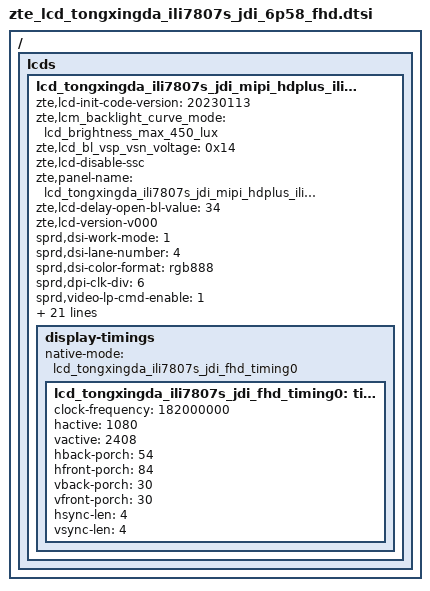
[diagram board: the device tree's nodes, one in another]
/ {
	fragment {
		target-path = "/";
		__overlay__ {
			lcds {
				lcd_tongxingda_ili7807s_jdi_mipi_hdplus_ilitek: lcd_tongxingda_ili7807s_jdi_mipi_hdplus_ilitek{
					zte,lcd-init-code-version = "20230113";

					zte,lcm_backlight_curve_mode = "lcd_brightness_max_450_lux";
					zte,lcd_bl_vsp_vsn_voltage = <0x14>;
					zte,lcd-disable-ssc;
					zte,panel-name = "lcd_tongxingda_ili7807s_jdi_mipi_hdplus_ilitek";
					zte,lcd-delay-open-bl-value = <34>;
					zte,lcd-version-v000;

					sprd,dsi-work-mode = <1>;
					sprd,dsi-lane-number = <4>;
					sprd,dsi-color-format = "rgb888";

					sprd,dpi-clk-div = <6>;
					sprd,video-lp-cmd-enable = <1>;
					sprd,hporch-lp-disable = <1>;

					sprd,phy-bit-clock = <1092000>;
					sprd,phy-escape-clock = <20000>;/* kHz */

					sprd,width-mm = <68430>;
					sprd,height-mm = <152570>;

					sprd,esd-check-enable = <1>;/* 0:close , 1:open */
					sprd,esd-check-mode = <1>;/* 0:REG ,1:TE  */
					sprd,esd-check-period = <2000>;
					sprd,esd-check-register = <0x0A>;
					sprd,esd-check-value = <0x9C>;

					sprd,dphy-taget-val = <5>;

					sprd,reset-on-sequence = <1 5>, <0 10>, <1 80>, <0 10>, <1 35>;
					sprd,reset-off-sequence = <1 20>;

					sprd,use-dcs-write;
		sprd,initial-command = [
				29 00 00 04 FF 78 07 01
				29 00 00 02 00 41
				29 00 00 02 01 42
				29 00 00 02 02 42
				29 00 00 02 03 2F
				29 00 00 02 04 c3
				29 00 00 02 05 03
				29 00 00 02 06 00
				29 00 00 02 07 0a

				29 00 00 02 08 01
				29 00 00 02 09 01
				29 00 00 02 0a 73
				29 00 00 02 0b 00
				29 00 00 02 0c 00
				29 00 00 02 0e 00

				29 00 00 02 16 01
				29 00 00 02 17 00
				29 00 00 02 18 30
				29 00 00 02 19 00
				29 00 00 02 1a 20
				29 00 00 02 1c 09

				29 00 00 02 31 07
				29 00 00 02 32 07
				29 00 00 02 33 07
				29 00 00 02 34 08
				29 00 00 02 35 07
				29 00 00 02 36 10
				29 00 00 02 37 07
				29 00 00 02 38 07
				29 00 00 02 39 1b
				29 00 00 02 3a 1a
				29 00 00 02 3b 19
				29 00 00 02 3c 18
				29 00 00 02 3d 07
				29 00 00 02 3e 07
				29 00 00 02 3f 07
				29 00 00 02 40 07
				29 00 00 02 41 07
				29 00 00 02 42 30
				29 00 00 02 43 2e
				29 00 00 02 44 2f
				29 00 00 02 45 07
				29 00 00 02 46 34
				29 00 00 02 47 35
				29 00 00 02 48 36

				29 00 00 02 49 07
				29 00 00 02 4a 29
				29 00 00 02 4b 07
				29 00 00 02 4c 00
				29 00 00 02 4d 07
				29 00 00 02 4e 10
				29 00 00 02 4f 07
				29 00 00 02 50 07
				29 00 00 02 51 1b
				29 00 00 02 52 1a
				29 00 00 02 53 19
				29 00 00 02 54 18
				29 00 00 02 55 07
				29 00 00 02 56 07
				29 00 00 02 57 07
				29 00 00 02 58 07
				29 00 00 02 59 07
				29 00 00 02 5a 30
				29 00 00 02 5b 2e
				29 00 00 02 5c 2f
				29 00 00 02 5d 07
				29 00 00 02 5e 34
				29 00 00 02 5f 35
				29 00 00 02 60 36

				29 00 00 02 61 07
				29 00 00 02 62 07
				29 00 00 02 63 07
				29 00 00 02 64 08
				29 00 00 02 65 07
				29 00 00 02 66 14
				29 00 00 02 67 07
				29 00 00 02 68 07
				29 00 00 02 69 18
				29 00 00 02 6a 19
				29 00 00 02 6b 1a
				29 00 00 02 6c 1b
				29 00 00 02 6d 07
				29 00 00 02 6e 07
				29 00 00 02 6f 07
				29 00 00 02 70 07
				29 00 00 02 71 07
				29 00 00 02 72 30
				29 00 00 02 73 2e
				29 00 00 02 74 2f
				29 00 00 02 75 07
				29 00 00 02 76 34
				29 00 00 02 77 35
				29 00 00 02 78 36

				29 00 00 02 79 07
				29 00 00 02 7a 29
				29 00 00 02 7b 07
				29 00 00 02 7c 00
				29 00 00 02 7d 07
				29 00 00 02 7e 14
				29 00 00 02 7f 07
				29 00 00 02 80 07
				29 00 00 02 81 18
				29 00 00 02 82 19
				29 00 00 02 83 1a
				29 00 00 02 84 1b
				29 00 00 02 85 07
				29 00 00 02 86 07
				29 00 00 02 87 07
				29 00 00 02 88 07
				29 00 00 02 89 07
				29 00 00 02 8a 30
				29 00 00 02 8b 2e
				29 00 00 02 8c 2f
				29 00 00 02 8d 07
				29 00 00 02 8e 34
				29 00 00 02 8f 35
				29 00 00 02 90 36

				29 00 00 02 a0 43
				29 00 00 02 a1 00
				29 00 00 02 a2 00
				29 00 00 02 a3 00
				29 00 00 02 a4 00
				29 00 00 02 a5 00
				29 00 00 02 a6 0a
				29 00 00 02 a7 40
				29 00 00 02 a8 10
				29 00 00 02 b0 00
				29 00 00 02 b1 05
				29 00 00 02 b2 00
				29 00 00 02 b3 08
				29 00 00 02 c5 0a
				29 00 00 02 c6 00
				29 00 00 02 c7 00
				29 00 00 02 c8 00
				29 00 00 02 c9 00
				29 00 00 02 ca 71
				29 00 00 02 d1 10
				29 00 00 02 d2 20
				29 00 00 02 d3 00
				29 00 00 02 d4 01
				29 00 00 02 d5 20
				29 00 00 02 d6 21
				29 00 00 02 d7 03
				29 00 00 02 d8 80
				29 00 00 02 d9 24
				29 00 00 02 da 01
				29 00 00 02 db 09
				29 00 00 02 dc 08
				29 00 00 02 dd c4
				29 00 00 02 de 00
				29 00 00 02 df 80
				29 00 00 02 e0 40
				29 00 00 02 e1 48
				29 00 00 02 e2 10
				29 00 00 02 e3 20
				29 00 00 02 e4 00
				29 00 00 02 e5 09
				29 00 00 02 e6 21
				29 00 00 02 ed 55
				29 00 00 02 ef 30
				29 00 00 02 f0 24
				29 00 00 02 f4 54

				29 00 00 04 FF 78 07 02
				29 00 00 02 40 02
				29 00 00 02 41 00
				29 00 00 02 42 07
				29 00 00 02 43 36
				29 00 00 02 53 07
				29 00 00 02 1B 02
				29 00 00 02 36 00
				29 00 00 02 46 11
				29 00 00 02 47 02
				29 00 00 02 4F 01
				29 00 00 02 76 13
				29 00 00 02 80 32
				29 00 00 02 5B 00
				29 00 00 02 F9 34
				29 00 00 02 06 6B
				29 00 00 02 08 00
				29 00 00 02 0E 22
				29 00 00 02 0F 28
				29 00 00 02 24 16

				29 00 00 04 FF 78 07 04
				29 00 00 02 B7 CF
				29 00 00 02 B8 45
				29 00 00 02 BA 74
				29 00 00 02 BD 01

				29 00 00 04 FF 78 07 05
				29 00 00 02 1F 00
				29 00 00 02 20 80
				29 00 00 02 61 CB
				29 00 00 02 72 60
				29 00 00 02 74 56
				29 00 00 02 76 58
				29 00 00 02 7A 50
				29 00 00 02 7B 7E
				29 00 00 02 7C 7E
				29 00 00 02 46 45
				29 00 00 02 47 55
				29 00 00 02 B5 45
				29 00 00 02 B7 55
				29 00 00 02 C6 1B
				29 00 00 02 3E 50
				29 00 00 02 56 FF

				29 00 00 04 FF 78 07 06
				29 00 00 02 80 00
				29 00 00 02 C0 68
				29 00 00 02 C1 19
				29 00 00 02 C3 06
				29 00 00 02 13 13
				29 00 00 02 12 BD

				29 00 00 04 FF 78 07 07
				29 00 00 02 11 16
				29 00 00 02 29 00
				29 00 00 02 03 20
				29 00 00 02 07 4C
				29 00 00 02 12 00

				29 00 00 04 FF 78 07 08
				29 00 00 20 E0 00 00 19 3E 00 78 A2 C4 14
							FA 23 61 25 91 DB 14 2A 4F 8C
							B6 3E ED 0E 44 3F 5E 7F AF 0F D0 D9
				29 00 00 20 E1 00 00 19 3E 00 78 A2 C4 14
							FA 23 61 25 91 DB 14 2A 4F 8C
							B6 3E ED 0E 44 3F 5E 7F AF 0F D0 D9

				29 00 00 04 FF 78 07 0B
				29 00 00 02 94 88
				29 00 00 02 95 22
				29 00 00 02 96 06
				29 00 00 02 97 06
				29 00 00 02 98 CB
				29 00 00 02 99 CB
				29 00 00 02 9A 46
				29 00 00 02 9B B6
				29 00 00 02 9C 05
				29 00 00 02 9D 05
				29 00 00 02 9E A8
				29 00 00 02 9F A8
				29 00 00 02 AA 12
				29 00 00 02 AB E0

				29 00 00 04 FF 78 07 0C
				29 00 00 02 80 2A
				29 00 00 02 81 C0
				29 00 00 02 82 29
				29 00 00 02 83 B8

				29 00 00 04 FF 78 07 0E
				29 00 00 02 00 A3

				29 00 00 02 B9 CC
				29 00 00 02 B3 00
				29 00 00 02 B4 33
				29 00 00 02 BD 00
				29 00 00 02 C1 80

				29 00 00 02 02 0F
				29 00 00 02 04 06
				29 00 00 02 13 04
				29 00 00 02 41 14
				29 00 00 02 42 02
				29 00 00 02 43 14
				29 00 00 02 44 82
				29 00 00 02 40 07
				29 00 00 02 45 0A
				29 00 00 02 46 E5
				29 00 00 02 47 10
				29 00 00 02 49 2C
				29 00 00 02 B0 00
				29 00 00 02 B1 62
				29 00 00 02 C0 02
				29 00 00 02 C2 62
				29 00 00 02 C3 62
				29 00 00 02 C4 62
				29 00 00 02 C5 62
				29 00 00 02 C6 62
				29 00 00 02 C7 62
				29 00 00 02 C8 62
				29 00 00 02 C9 62
				29 00 00 02 4D C2
				29 00 00 02 50 00
				29 00 00 02 4B 01

				29 00 00 02 05 20
				29 00 00 02 E0 07
				29 00 00 02 E2 07
				29 00 00 02 E3 36
				29 00 00 02 E5 07

				29 00 00 04 FF 78 07 1E
				29 00 00 02 C9 02
				29 00 00 02 C0 1F
				29 00 00 02 C1 00
				29 00 00 02 C2 00
				29 00 00 02 C3 00
				29 00 00 02 C4 19
				29 00 00 02 C7 00

				29 00 00 04 FF 78 07 00
				29 00 00 02 35 00
				05 78 00 01 11
				05 32 00 01 29

				29 00 00 04 FF 78 07 01
				29 00 00 02 F2 FC
				29 00 00 02 F3 FC
				29 00 00 02 F5 FC
				29 00 00 02 F6 FC
				29 0A 00 04 FF 78 07 00		
		];

					sprd,sleep-in-command = [
						29 0A 00 04 FF 78 07 00
						15 1E 00 01 28
						15 78 00 01 10
						];
					sprd,sleep-out-command = [
						29 0A 00 04 FF 78 07 00
						15 78 00 01 11
						15 32 00 01 29
						];

					display-timings {
						native-mode = <&lcd_tongxingda_ili7807s_jdi_fhd_timing0>;
						lcd_tongxingda_ili7807s_jdi_fhd_timing0: timing0 {
							clock-frequency = <182000000>;
							hactive = <1080>;
							vactive = <2408>;
							hback-porch = <54>;
							hfront-porch = <84>;
							vback-porch = <30>;
							vfront-porch = <30>;
							hsync-len = <4>;
							vsync-len = <4>;
						};
						/*icnl9911c2_tongxingda_timing1: timing1 {
							clock-frequency = <128000000>;
 							hactive = <720>;
 							vactive = <1600>;
 							hback-porch = <36>;
 							hfront-porch = <36>;
 							vback-porch = <32>;
							vfront-porch = <160>;
 							hsync-len = <4>;
 							vsync-len = <4>;
 
						};*/
					};
					/*
					oled-backlight {
						default-brightness-level = <1632>;
						sprd,max-level = <4095>;
						brightness-levels = [
							39 00 00 03 51 00 00
							39 00 00 02 53 2C
						];
					};*/
				};
			};
		};
	};
};
